# SF32LB58x register map
File version: 1.0
CPU: CM33 r0p1, little endian, MPU, FPU, 3 interrupt priority bits
Registers are 32-bit, read-write, reset 0x0 unless marked. A register's access mark holds for its fields unless they carry their own. Offsets are from the block's base; [hi:lo] are bit positions; {n}, {i} and the like mark numbered series.

## AES
Base 0x4000D000
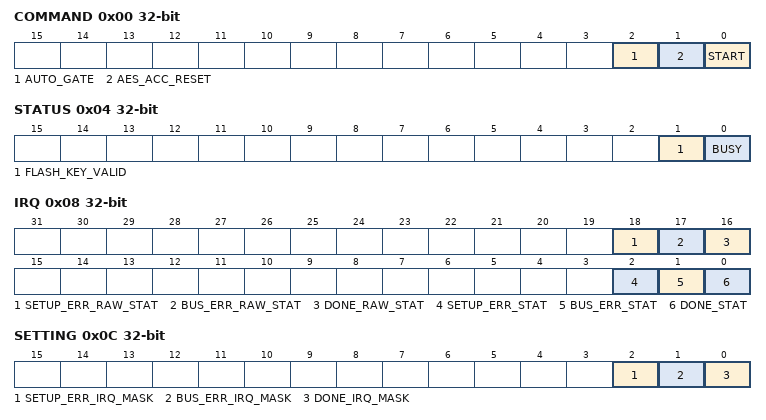
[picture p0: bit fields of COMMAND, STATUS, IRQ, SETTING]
0x00 COMMAND
  [2] AUTO_GATE — auto clock gating
  [1] AES_ACC_RESET — AES_ACC soft reset, 1'h1: reset the AES_ACC block
  [0] START — write 1 to trigger the AES_ACC block
0x04 STATUS
  [1] FLASH_KEY_VALID — flash key valid indicator
  [0] BUSY — AES_ACC block is busy
0x08 IRQ
  [18] SETUP_ERR_RAW_STAT — setup error raw status
  [17] BUS_ERR_RAW_STAT — bus error raw status
  [16] DONE_RAW_STAT — done raw status
  [2] SETUP_ERR_STAT — setup error status
  [1] BUS_ERR_STAT — bus error status
  [0] DONE_STAT — done status
0x0C SETTING
  [2] SETUP_ERR_IRQ_MASK — setup error interrupt mask, 0: mask the interrupt
  [1] BUS_ERR_IRQ_MASK — bus error interrupt mask, 0: mask the interrupt
  [0] DONE_IRQ_MASK — done interrupt mask, 0: mask the interrupt
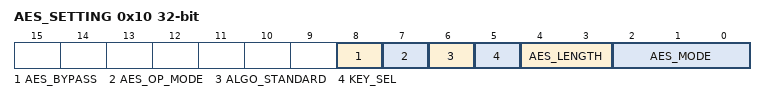
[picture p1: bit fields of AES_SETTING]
0x10 AES_SETTING
  [8] AES_BYPASS — 1'h0: normal operation 1'h1: bypass
  [7] AES_OP_MODE — 1'h0: decryption 1'h1: encryption
  [6] ALGO_STANDARD — 1'h0: AES 1'h1: SM4
  [5] KEY_SEL — 1'h0: select key from AES_ACC key registers 1'h1: use internal root key
  [4:3] AES_LENGTH — AES Length: 2'h0: 128-bit 2'h1: 192-bit 2'h2: 256-bit 2'h3: Reserved
  [2:0] AES_MODE — AES Mode: 3'h0: ECB 3'h1: CTR 3'h2: CBC Others: Reserved
0x14 DMA_IN
  [31:0] ADDR — input data address
0x18 DMA_OUT
  [31:0] ADDR — output data address
0x1C DMA_DATA
  [27:0] SIZE — data block size, AES_ACC only support block aligned transaction. Each block contains 16 bytes.
{0x20+4i} IV_W{i} (i=0..3)
  [31:0] DATA — Initial Vector Word{i}
{0x30+4i} EXT_KEY_W{i} (i=0..7)
  [31:0] DATA — External Key Word{i}

## TRNG
Base 0x4000F000
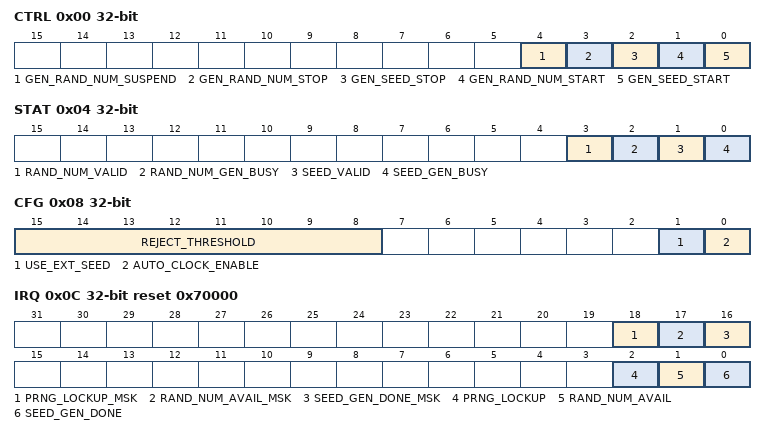
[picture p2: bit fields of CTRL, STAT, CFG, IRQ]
0x00 CTRL
  [4] GEN_RAND_NUM_SUSPEND — Set 1 to suspend random number generation and update. Set 0 to recover the process.
  [3] GEN_RAND_NUM_STOP — Set 1 to stop random number generation and update. This will reset the random number generation engine. After release the stop bit, user should write 1 to gen_rand_num_start to trigger the random number engine.
  [2] GEN_SEED_STOP — Set 1 to stop random seed generation. This will reset the random seed generation engine. After release the stop bit, user should write 1 to gen_seed_start to trigger the random seed engine.
  [1] GEN_RAND_NUM_START — write 1 to trigger the random number generation engine
  [0] GEN_SEED_START — write 1 to trigger the random seed generation engine
0x04 STAT
  [3] RAND_NUM_VALID — random number valid flag
  [2] RAND_NUM_GEN_BUSY — random number engine busy flag
  [1] SEED_VALID — random seed valid flag
  [0] SEED_GEN_BUSY — random seed engine busy flag
0x08 CFG
  [15:8] REJECT_THRESHOLD — random seed internal VN corrector check threshold
  [1] USE_EXT_SEED — set 1 to use external seed to generate random number
  [0] AUTO_CLOCK_ENABLE — auto clock gating enable
0x0C IRQ reset 0x70000
  [18] PRNG_LOCKUP_MSK — prng lockup interrupt mask
  [17] RAND_NUM_AVAIL_MSK — random number available interrupt mask
  [16] SEED_GEN_DONE_MSK — random seed generation done interrupt mask
  [2] PRNG_LOCKUP — prng lockup raw interrupt
  [1] RAND_NUM_AVAIL — random number available raw interrupt
  [0] SEED_GEN_DONE — random seed generation done raw interrupt
{0x10+4i} RAND_SEED{i} (i=0..7)
  [31:0] VAL — random seed value{i}. If using external random seed, write value to this register will update the random seed in use.
{0x30+4i} RAND_NUM{i} (i=0..7)
  [31:0] VAL — random number value{i}
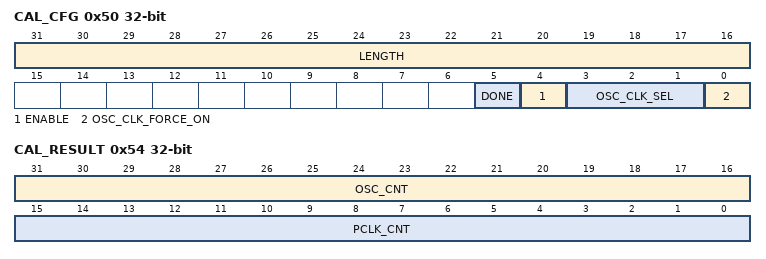
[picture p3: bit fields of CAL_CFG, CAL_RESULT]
0x50 CAL_CFG
  [31:16] LENGTH — calibration length
  [5] DONE — calibration done
  [4] ENABLE — calibration enable
  [3:1] OSC_CLK_SEL — osc clock select
  [0] OSC_CLK_FORCE_ON — osc force enable
0x54 CAL_RESULT
  [31:16] OSC_CNT — osc clock calibration counter result
  [15:0] PCLK_CNT — pclk calibration counter result
